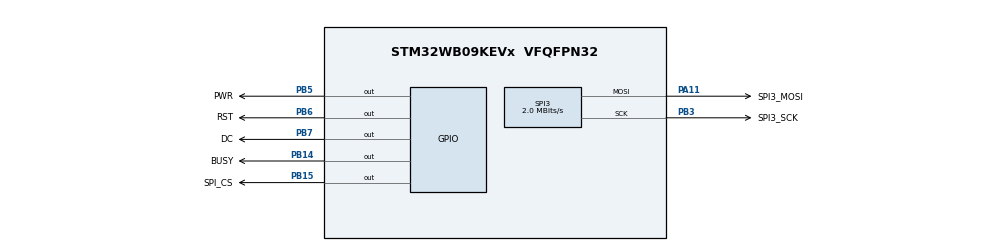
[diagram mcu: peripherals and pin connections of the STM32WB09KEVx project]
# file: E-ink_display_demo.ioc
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Mcu.Family=STM32WB0
Mcu.Name=STM32WB09KEVx
Mcu.Package=VFQFPN32
NUCLEO-WB09KE.LD1=true
NUCLEO-WB09KE.LD2=true
NUCLEO-WB09KE.LD3=true
NUCLEO-WB09KE.VCP=false
OSCIN.GPIO_Label=OSC_IN
OSCIN.Signal=RCC_OSC_IN
OSCOUT.GPIO_Label=OSC_OUT
OSCOUT.Signal=RCC_OSC_OUT
PA11.GPIO_Label=SPI3_MOSI
PA11.GPIO_Speed=GPIO_SPEED_FREQ_VERY_HIGH
PA11.Mode=TX_Only_Simplex_Unidirect_Master
PA11.Signal=SPI3_MOSI
PA8.GPIO_Label=SPI3_MISO
PA8.GPIO_Speed=GPIO_SPEED_FREQ_VERY_HIGH
PA8.Signal=SPI3_MISO
PA9.GPIO_Label=SPI3_NSS
PA9.GPIO_Speed=GPIO_SPEED_FREQ_VERY_HIGH
PA9.Signal=SPI3_NSS
PB12.GPIO_Label=OSC32_OUT
PB12.Signal=RCC_OSC32_OUT
PB13.GPIO_Label=OSC32_IN
PB13.Signal=RCC_OSC32_IN
PB14.GPIO_Label=BUSY
PB14.Signal=GPIO_Output
PB15.GPIO_Label=SPI_CS
PB15.Signal=GPIO_Output
PB3.GPIO_Label=SPI3_SCK
PB3.GPIO_Speed=GPIO_SPEED_FREQ_VERY_HIGH
PB3.Mode=TX_Only_Simplex_Unidirect_Master
PB3.Signal=SPI3_SCK
PB5.GPIO_Label=PWR
PB5.Signal=GPIO_Output
PB6.GPIO_FM6=__NULL
PB6.GPIO_Label=RST
PB6.GPIO_PuPd=GPIO_NOPULL
PB6.Signal=GPIO_Output
PB7.GPIO_Label=DC
PB7.Signal=GPIO_Output
ProjectManager.HeapSize=0x000
ProjectManager.StackSize=0xC00
ProjectManager.TargetToolchain=CMake
RCC.HSE_VALUE=32000000
RCC.HSI_VALUE=64000000
RCC.LSE_Timout=100
RCC.LSE_VALUE=32768
SPI3.BaudRatePrescaler=SPI_BAUDRATEPRESCALER_32
SPI3.CalculateBaudRate=2.0 MBits/s
SPI3.DataSize=SPI_DATASIZE_8BIT
SPI3.Direction=SPI_DIRECTION_2LINES
SPI3.Mode=SPI_MODE_MASTER
SPI3.NSSPMode=SPI_NSS_PULSE_ENABLE
SPI3.VirtualType=VM_MASTER
VP_MEMORYMAP_VS_MEMORYMAP.Mode=CurAppReg
VP_NUCLEO-WB09KE_VS_BSP_COMMON.Mode=COMMON
VP_PWR_VS_SECSignals.Mode=Security/Privilege
board=NUCLEO-WB09KE

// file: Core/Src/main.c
/* USER CODE BEGIN Header */
/**
  ******************************************************************************
  * @file           : main.c
  * @brief          : Main program body
  ******************************************************************************
  * @attention
  *
  * Copyright (c) 2026 STMicroelectronics.
  * All rights reserved.
  *
  * This software is licensed under terms that can be found in the LICENSE file
  * in the root directory of this software component.
  * If no LICENSE file comes with this software, it is provided AS-IS.
  *
  ******************************************************************************
  */
/* USER CODE END Header */
#include "main.h"
//#include "e-ink_test/DEV_Config.h"
#include "e-ink_test/EPD_Test.h"
#include "stm32wb0x_hal_gpio.h"

SPI_HandleTypeDef hspi3;

void SystemClock_Config(void);
void PeriphCommonClock_Config(void);
static void MX_GPIO_Init(void);
static void MX_SPI3_Init(void);

int main(void)
{

  /* MCU Configuration--------------------------------------------------------*/

  /* Reset of all peripherals, Initializes the Flash interface and the Systick. */
  HAL_Init();

  /* Configure the system clock */
  SystemClock_Config();

  /* Configure the peripherals common clocks */
  PeriphCommonClock_Config();

  /* Initialize all configured peripherals */
  MX_GPIO_Init();
  MX_SPI3_Init();

  /* Initialize leds */
  BSP_LED_Init(LED_BLUE);
  BSP_LED_Init(LED_GREEN);
  BSP_LED_Init(LED_RED);

  /* Infinite loop */
  /* USER CODE BEGIN WHILE */
  int delay = 1000; //1 sec

  //Display test
  EPD_test();

  while (1)
  {

    /* -- Sample board code for User push-button in interrupt mode ---- */
    ///*
    BSP_LED_Toggle(LED_BLUE);
    HAL_Delay(delay);

    BSP_LED_Toggle(LED_GREEN);
    HAL_Delay(delay);

    BSP_LED_Toggle(LED_RED);
    HAL_Delay(delay);
    //*/

    /* USER CODE END WHILE */

    /* USER CODE BEGIN 3 */
    //Pin test
    /*
    HAL_GPIO_WritePin(EPD_RST_PIN, GPIO_PIN_SET);
    HAL_Delay(delay);
    HAL_GPIO_WritePin(EPD_RST_PIN, GPIO_PIN_RESET);
    HAL_Delay(delay);
    */
  }
  /* USER CODE END 3 */
}

void SystemClock_Config(void)
{
  RCC_ClkInitTypeDef RCC_ClkInitStruct = {0};

  /** Configure the SYSCLKSource and SYSCLKDivider
  */
  RCC_ClkInitStruct.SYSCLKSource = RCC_SYSCLKSOURCE_HSI;
  RCC_ClkInitStruct.SYSCLKDivider = RCC_RC64MPLL_DIV1;

  if (HAL_RCC_ClockConfig(&RCC_ClkInitStruct, FLASH_WAIT_STATES_1) != HAL_OK)
  {
    Error_Handler();
  }
}

void PeriphCommonClock_Config(void)
{
  RCC_PeriphCLKInitTypeDef PeriphClkInitStruct = {0};

  /** Initializes the peripherals clock
  */
  PeriphClkInitStruct.PeriphClockSelection = RCC_PERIPHCLK_SMPS;
  PeriphClkInitStruct.SmpsDivSelection = RCC_SMPSCLK_DIV4;

  if (HAL_RCCEx_PeriphCLKConfig(&PeriphClkInitStruct) != HAL_OK)
  {
    Error_Handler();
  }
}

static void MX_SPI3_Init(void)
{

  /* SPI3 parameter configuration*/
  hspi3.Instance = SPI3;
  hspi3.Init.Mode = SPI_MODE_MASTER;
  hspi3.Init.Direction = SPI_DIRECTION_2LINES;
  hspi3.Init.DataSize = SPI_DATASIZE_8BIT;
  hspi3.Init.CLKPolarity = SPI_POLARITY_LOW;
  hspi3.Init.CLKPhase = SPI_PHASE_1EDGE;
  hspi3.Init.NSS = SPI_NSS_SOFT;
  hspi3.Init.BaudRatePrescaler = SPI_BAUDRATEPRESCALER_32;
  hspi3.Init.FirstBit = SPI_FIRSTBIT_MSB;
  hspi3.Init.TIMode = SPI_TIMODE_DISABLE;
  hspi3.Init.CRCCalculation = SPI_CRCCALCULATION_DISABLE;
  hspi3.Init.CRCPolynomial = 7;
  hspi3.Init.CRCLength = SPI_CRC_LENGTH_DATASIZE;
  hspi3.Init.NSSPMode = SPI_NSS_PULSE_ENABLE;
  if (HAL_SPI_Init(&hspi3) != HAL_OK)
  {
    Error_Handler();
  }

}

static void MX_GPIO_Init(void)
{
  GPIO_InitTypeDef GPIO_InitStruct = {0};

  /* GPIO Ports Clock Enable */
  __HAL_RCC_GPIOB_CLK_ENABLE();
  __HAL_RCC_GPIOA_CLK_ENABLE();

  /*Configure GPIO pin Output Level */
  HAL_GPIO_WritePin(GPIOB, SPI_CS_Pin|BUSY_Pin|DC_Pin|RST_Pin
                          |PWR_Pin, GPIO_PIN_RESET);

  /*Configure GPIO pins : SPI_CS_Pin BUSY_Pin DC_Pin RST_Pin
                           PWR_Pin */
  GPIO_InitStruct.Pin = SPI_CS_Pin|BUSY_Pin|DC_Pin|RST_Pin
                          |PWR_Pin;
  GPIO_InitStruct.Mode = GPIO_MODE_OUTPUT_PP;
  GPIO_InitStruct.Pull = GPIO_NOPULL;
  GPIO_InitStruct.Speed = GPIO_SPEED_FREQ_LOW;
  HAL_GPIO_Init(GPIOB, &GPIO_InitStruct);

  /**/
  HAL_PWREx_DisableGPIOPullUp(PWR_GPIO_B, PWR_GPIO_BIT_15|PWR_GPIO_BIT_14|PWR_GPIO_BIT_7|PWR_GPIO_BIT_6
                          |PWR_GPIO_BIT_5);

  /**/
  HAL_PWREx_DisableGPIOPullDown(PWR_GPIO_B, PWR_GPIO_BIT_15|PWR_GPIO_BIT_14|PWR_GPIO_BIT_7|PWR_GPIO_BIT_6
                          |PWR_GPIO_BIT_5);

}

void Error_Handler(void)
{
  __disable_irq();
  while (1)
  {
  }
}
